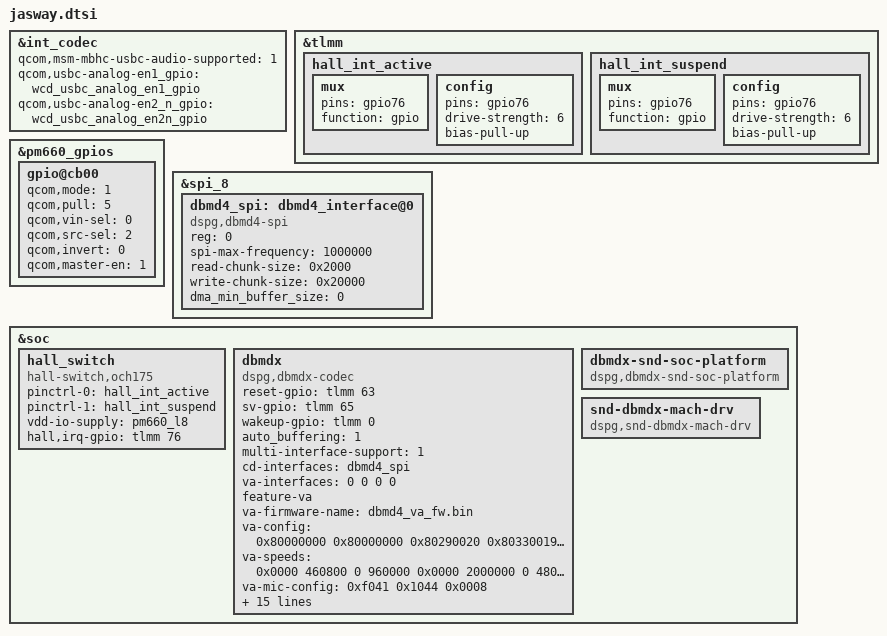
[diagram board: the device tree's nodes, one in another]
// SPDX-License-Identifier: GPL-2.0

#include "longcheer/common/longcheer-sdm660-base.dtsi"
#include "longcheer/wayne/wayne-common-base.dtsi"

/* Jasmine/Wayne specific diff */
&int_codec {
	qcom,msm-mbhc-usbc-audio-supported = <1>;
	qcom,usbc-analog-en1_gpio = <&wcd_usbc_analog_en1_gpio>;
	qcom,usbc-analog-en2_n_gpio = <&wcd_usbc_analog_en2n_gpio>;
};

&tlmm {
	hall_int_active: hall_int_active {
		mux {
			pins = "gpio76";
			function = "gpio";
		};

		config {
			pins = "gpio76";
			drive-strength = <6>;
			bias-pull-up;
		};
	};

	hall_int_suspend: hall_int_suspend {
		mux {
			pins = "gpio76";
			function = "gpio";
		};

		config {
			pins = "gpio76";
			drive-strength = <6>;
			bias-pull-up;
		};
	};
};

&pm660_gpios {
	 gpio@cb00 {
		qcom,mode = <1>;
		qcom,pull = <5>;
		qcom,vin-sel = <0>;
		qcom,src-sel = <2>;
		qcom,invert = <0>;
		qcom,master-en = <1>;
		status = "ok";
	};
};

&spi_8{
	status = "ok";
	
	dbmd4_spi: dbmd4_interface@0 {
		compatible = "dspg,dbmd4-spi";
		reg = <0>;
		spi-max-frequency = <1000000>;
		read-chunk-size  = <0x2000>;
		write-chunk-size = <0x20000>;
		dma_min_buffer_size = <0>;
	};
};

&soc {
	hall_switch {
	    compatible = "hall-switch,och175";
	    pinctrl-names = "hall_active","hall_suspend";
	    pinctrl-0 = <&hall_int_active>;
	    pinctrl-1 = <&hall_int_suspend>;
	    vdd-io-supply= <&pm660_l8>;
	    interrupt-names = "hall_irq";
	    hall,irq-gpio = <&tlmm 76 0x0>;
	};

	dbmdx {
		compatible = "dspg,dbmdx-codec";
		status = "okay";
		reset-gpio = <&tlmm 63 0>;
		sv-gpio = <&tlmm 65 0>;
		wakeup-gpio = <&tlmm 0 0>;
		auto_buffering = <1>;
		multi-interface-support = <1>;
		cd-interfaces = <&dbmd4_spi>;
		va-interfaces = <0 0 0 0>;
		feature-va;
		va-firmware-name = "dbmd4_va_fw.bin";
		va-config = <0x80000000
					 0x80000000
					 0x80290020
					 0x80330019
					 0x802210e4
					 0x80158E8E
					 0x801b0020
					 0x80230001
					 0x801A0017
					 0x80103015
					 0x80000000
					 0x80000000
					 0x80000000>;
		va-speeds = <0x0000 460800  0 960000
					 0x0000 2000000 0 4800000
					 0x0000 3000000 0 4800000>;
		va-mic-config = <0xf041 0x1044 0x0008>;
		va-mic-mode = <4>;
		master-clk-rate = <32768>;
		firmware_id = <0xdbd4>;
		use_gpio_for_wakeup = <1>;
		wakeup_set_value = <0>;
		auto_detection = <1>;
		detection_buffer_channels = <0>;
		min_samples_chunk_size = <128>;
		pcm_streaming_mode = <1>;
		boot_options = <0x200>;
		amodel_options = <0x4>;
		send_uevent_on_detection = <1>;
		send_uevent_after_buffering = <0>;
		detection_after_buffering = <0>;
		va_backlog_length = <0x7d0>;
	};

	dbmdx-snd-soc-platform {
		compatible = "dspg,dbmdx-snd-soc-platform";
	};

	snd-dbmdx-mach-drv {
		compatible = "dspg,snd-dbmdx-mach-drv";
	};
};
